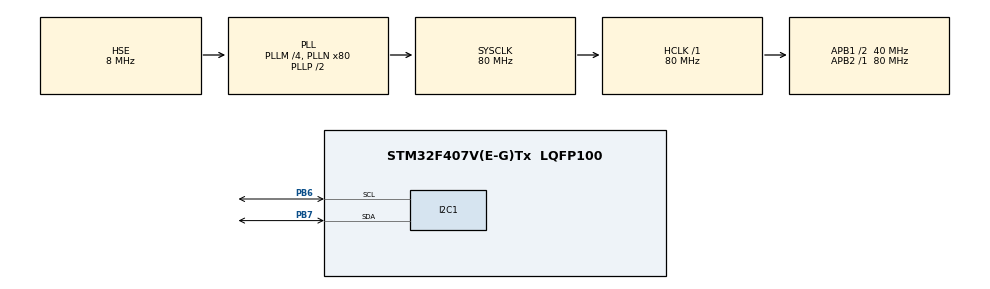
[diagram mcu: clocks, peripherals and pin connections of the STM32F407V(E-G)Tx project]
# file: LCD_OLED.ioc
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Dma.I2C1_TX.0.Direction=DMA_MEMORY_TO_PERIPH
Dma.I2C1_TX.0.FIFOMode=DMA_FIFOMODE_DISABLE
Dma.I2C1_TX.0.Instance=DMA1_Stream6
Dma.I2C1_TX.0.MemDataAlignment=DMA_MDATAALIGN_BYTE
Dma.I2C1_TX.0.MemInc=DMA_MINC_ENABLE
Dma.I2C1_TX.0.Mode=DMA_NORMAL
Dma.I2C1_TX.0.PeriphDataAlignment=DMA_PDATAALIGN_BYTE
Dma.I2C1_TX.0.PeriphInc=DMA_PINC_DISABLE
Dma.I2C1_TX.0.Priority=DMA_PRIORITY_LOW
Dma.Request0=I2C1_TX
Mcu.Family=STM32F4
Mcu.Name=STM32F407V(E-G)Tx
Mcu.Package=LQFP100
NVIC.DMA1_Stream6_IRQn=true\:0\:0\:false\:false\:true\:false\:true\:true
NVIC.I2C1_EV_IRQn=true\:0\:0\:false\:false\:true\:true\:true\:true
NVIC.PriorityGroup=NVIC_PRIORITYGROUP_4
PA13.Mode=Serial_Wire
PA13.Signal=SYS_JTMS-SWDIO
PA14.Mode=Serial_Wire
PA14.Signal=SYS_JTCK-SWCLK
PB6.Mode=I2C
PB6.Signal=I2C1_SCL
PB7.Mode=I2C
PB7.Signal=I2C1_SDA
PH0-OSC_IN.Mode=HSE-External-Oscillator
PH0-OSC_IN.Signal=RCC_OSC_IN
PH1-OSC_OUT.Mode=HSE-External-Oscillator
PH1-OSC_OUT.Signal=RCC_OSC_OUT
ProjectManager.HeapSize=0x200
ProjectManager.StackSize=0x400
ProjectManager.TargetToolchain=STM32CubeIDE
RCC.48MHZClocksFreq_Value=40000000
RCC.AHBFreq_Value=80000000
RCC.APB1CLKDivider=RCC_HCLK_DIV2
RCC.APB1Freq_Value=40000000
RCC.APB1TimFreq_Value=80000000
RCC.APB2Freq_Value=80000000
RCC.APB2TimFreq_Value=80000000
RCC.CortexFreq_Value=80000000
RCC.HCLKFreq_Value=80000000
RCC.HSE_VALUE=8000000
RCC.HSI_VALUE=16000000
RCC.LSE_VALUE=32768
RCC.PLLM=4
RCC.PLLN=80
RCC.PLLSourceVirtual=RCC_PLLSOURCE_HSE
RCC.SYSCLKFreq_VALUE=80000000
RCC.SYSCLKSource=RCC_SYSCLKSOURCE_PLLCLK
RCC.VCOOutputFreq_Value=160000000
board=custom

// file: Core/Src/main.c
/* USER CODE BEGIN Header */
/**
  ******************************************************************************
  * @file           : main.c
  * @brief          : Main program body
  ******************************************************************************
  * @attention
  *
  * Copyright (c) 2023 STMicroelectronics.
  * All rights reserved.
  *
  * This software is licensed under terms that can be found in the LICENSE file
  * in the root directory of this software component.
  * If no LICENSE file comes with this software, it is provided AS-IS.
  *
  ******************************************************************************
  */
/* USER CODE END Header */
#include "main.h"
#include "SSD1306.h"

I2C_HandleTypeDef hi2c1;
DMA_HandleTypeDef hdma_i2c1_tx;

void SystemClock_Config(void);
static void MX_GPIO_Init(void);
static void MX_DMA_Init(void);
static void MX_I2C1_Init(void);

int main(void)
{

  /* MCU Configuration--------------------------------------------------------*/

  /* Reset of all peripherals, Initializes the Flash interface and the Systick. */
  HAL_Init();

  /* Configure the system clock */
  SystemClock_Config();

  /* Initialize all configured peripherals */
  MX_GPIO_Init();
  MX_DMA_Init();
  MX_I2C1_Init();
  /* USER CODE BEGIN 2 */

  // Inicializa OLED display
    ssd1306_Init();

   // Clear OLED display
    ssd1306_Clear();
   //
    ssd1306_SetColor(White);

  /* USER CODE END 2 */

  /* Infinite loop */
  /* USER CODE BEGIN WHILE */
  while (1)
  {

	     ssd1306_Clear();
	     ssd1306_SetCursor(8, 4);
	     ssd1306_WriteString("Driver", Font_16x26);
	     ssd1306_UpdateScreen();
	     HAL_Delay(2000);
	     ssd1306_Clear();
	     ssd1306_SetCursor(16, 1);
	     ssd1306_WriteString("LCD", Font_16x26);
	     ssd1306_SetCursor(20,25);
	     ssd1306_WriteString("OLED", Font_16x26);
	     ssd1306_UpdateScreen();
	     HAL_Delay(2000);
	     ssd1306_Clear();
	     ssd1306_SetCursor(8, 4);
	     ssd1306_WriteString("ChatGPT", Font_16x26);
	     ssd1306_UpdateScreen();
	     HAL_Delay(2000);

    /* USER CODE END WHILE */

  }
}

void SystemClock_Config(void)
{
  RCC_OscInitTypeDef RCC_OscInitStruct = {0};
  RCC_ClkInitTypeDef RCC_ClkInitStruct = {0};

  /** Configure the main internal regulator output voltage
  */
  __HAL_RCC_PWR_CLK_ENABLE();
  __HAL_PWR_VOLTAGESCALING_CONFIG(PWR_REGULATOR_VOLTAGE_SCALE1);

  /** Initializes the RCC Oscillators according to the specified parameters
  * in the RCC_OscInitTypeDef structure.
  */
  RCC_OscInitStruct.OscillatorType = RCC_OSCILLATORTYPE_HSE;
  RCC_OscInitStruct.HSEState = RCC_HSE_ON;
  RCC_OscInitStruct.PLL.PLLState = RCC_PLL_ON;
  RCC_OscInitStruct.PLL.PLLSource = RCC_PLLSOURCE_HSE;
  RCC_OscInitStruct.PLL.PLLM = 4;
  RCC_OscInitStruct.PLL.PLLN = 80;
  RCC_OscInitStruct.PLL.PLLP = RCC_PLLP_DIV2;
  RCC_OscInitStruct.PLL.PLLQ = 4;
  if (HAL_RCC_OscConfig(&RCC_OscInitStruct) != HAL_OK)
  {
    Error_Handler();
  }

  /** Initializes the CPU, AHB and APB buses clocks
  */
  RCC_ClkInitStruct.ClockType = RCC_CLOCKTYPE_HCLK|RCC_CLOCKTYPE_SYSCLK
                              |RCC_CLOCKTYPE_PCLK1|RCC_CLOCKTYPE_PCLK2;
  RCC_ClkInitStruct.SYSCLKSource = RCC_SYSCLKSOURCE_PLLCLK;
  RCC_ClkInitStruct.AHBCLKDivider = RCC_SYSCLK_DIV1;
  RCC_ClkInitStruct.APB1CLKDivider = RCC_HCLK_DIV2;
  RCC_ClkInitStruct.APB2CLKDivider = RCC_HCLK_DIV1;

  if (HAL_RCC_ClockConfig(&RCC_ClkInitStruct, FLASH_LATENCY_2) != HAL_OK)
  {
    Error_Handler();
  }
}

static void MX_I2C1_Init(void)
{

  hi2c1.Instance = I2C1;
  hi2c1.Init.ClockSpeed = 100000;
  hi2c1.Init.DutyCycle = I2C_DUTYCYCLE_2;
  hi2c1.Init.OwnAddress1 = 0;
  hi2c1.Init.AddressingMode = I2C_ADDRESSINGMODE_7BIT;
  hi2c1.Init.DualAddressMode = I2C_DUALADDRESS_DISABLE;
  hi2c1.Init.OwnAddress2 = 0;
  hi2c1.Init.GeneralCallMode = I2C_GENERALCALL_DISABLE;
  hi2c1.Init.NoStretchMode = I2C_NOSTRETCH_DISABLE;
  if (HAL_I2C_Init(&hi2c1) != HAL_OK)
  {
    Error_Handler();
  }

}

static void MX_DMA_Init(void)
{

  /* DMA controller clock enable */
  __HAL_RCC_DMA1_CLK_ENABLE();

  /* DMA interrupt init */
  /* DMA1_Stream6_IRQn interrupt configuration */
  HAL_NVIC_SetPriority(DMA1_Stream6_IRQn, 0, 0);
  HAL_NVIC_EnableIRQ(DMA1_Stream6_IRQn);

}

static void MX_GPIO_Init(void)
{

  /* GPIO Ports Clock Enable */
  __HAL_RCC_GPIOH_CLK_ENABLE();
  __HAL_RCC_GPIOA_CLK_ENABLE();
  __HAL_RCC_GPIOB_CLK_ENABLE();

}

void Error_Handler(void)
{
  __disable_irq();
  while (1)
  {
  }
}
